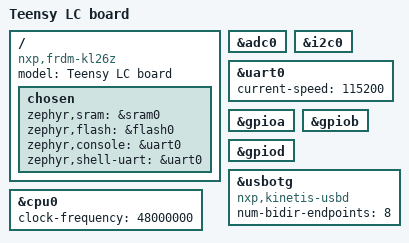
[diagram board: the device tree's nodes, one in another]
/* SPDX-License-Identifier: Apache-2.0 */

/dts-v1/;

#include <nxp/nxp_kl26z.dtsi>

/ {
	model = "Teensy LC board";
	compatible = "nxp,frdm-kl26z", "nxp,kl26z", "nxp,mkl26z4";

	chosen {
		zephyr,sram = &sram0;
		zephyr,flash = &flash0;
		zephyr,console = &uart0;
		zephyr,shell-uart = &uart0;
	};
};

&cpu0 {
	clock-frequency = <48000000>;
};

&adc0 {
	status = "okay";
};

&i2c0 {
	status = "okay";
};

&uart0 {
	status = "okay";
	current-speed = <115200>;
};

&gpioa {
	status = "okay";
};

&gpiob {
	status = "okay";
};

&gpiod {
	status = "okay";
};

&usbotg {
	compatible = "nxp,kinetis-usbd";
	status = "okay";
	num-bidir-endpoints = <8>;
};
